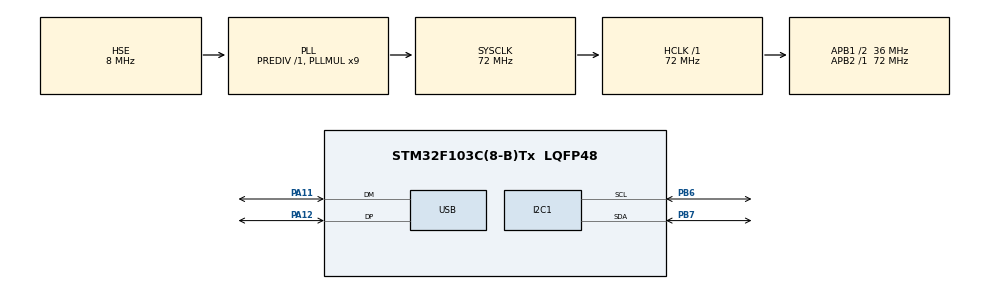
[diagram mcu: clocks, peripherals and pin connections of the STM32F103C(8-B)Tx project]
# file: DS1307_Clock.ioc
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Mcu.Family=STM32F1
Mcu.Name=STM32F103C(8-B)Tx
Mcu.Package=LQFP48
NVIC.PriorityGroup=NVIC_PRIORITYGROUP_4
NVIC.USB_LP_CAN1_RX0_IRQn=true\:0\:0\:false\:false\:true\:false\:true\:true
PA11.Mode=Device
PA11.Signal=USB_DM
PA12.Mode=Device
PA12.Signal=USB_DP
PA13.Mode=Serial_Wire
PA13.Signal=SYS_JTMS-SWDIO
PA14.Mode=Serial_Wire
PA14.Signal=SYS_JTCK-SWCLK
PB6.Mode=I2C
PB6.Signal=I2C1_SCL
PB7.Mode=I2C
PB7.Signal=I2C1_SDA
PD0-OSC_IN.Mode=HSE-External-Oscillator
PD0-OSC_IN.Signal=RCC_OSC_IN
PD1-OSC_OUT.Mode=HSE-External-Oscillator
PD1-OSC_OUT.Signal=RCC_OSC_OUT
ProjectManager.HeapSize=0x200
ProjectManager.StackSize=0x400
ProjectManager.TargetToolchain=STM32CubeIDE
RCC.AHBFreq_Value=72000000
RCC.APB1CLKDivider=RCC_HCLK_DIV2
RCC.APB1Freq_Value=36000000
RCC.APB1TimFreq_Value=72000000
RCC.APB2Freq_Value=72000000
RCC.APB2TimFreq_Value=72000000
RCC.HCLKFreq_Value=72000000
RCC.PLLMUL=RCC_PLL_MUL9
RCC.SYSCLKFreq_VALUE=72000000
RCC.SYSCLKSource=RCC_SYSCLKSOURCE_PLLCLK
RCC.USBFreq_Value=48000000
RCC.USBPrescaler=RCC_USBCLKSOURCE_PLL_DIV1_5
USB_DEVICE.CLASS_NAME_FS=CDC
USB_DEVICE.VirtualMode=Cdc
USB_DEVICE.VirtualModeFS=Cdc_FS
VP_USB_DEVICE_VS_USB_DEVICE_CDC_FS.Mode=CDC_FS
board=custom

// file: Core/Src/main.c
/* USER CODE BEGIN Header */
/**
  ******************************************************************************
  * @file           : main.c
  * @brief          : Main program body
  ******************************************************************************
  * @attention
  *
  * Copyright (c) 2024 STMicroelectronics.
  * All rights reserved.
  *
  * This software is licensed under terms that can be found in the LICENSE file
  * in the root directory of this software component.
  * If no LICENSE file comes with this software, it is provided AS-IS.
  *
  ******************************************************************************
  */
/* USER CODE END Header */
#include "main.h"
#include "usb_device.h"
#include "usbd_cdc_if.h"
#include "E:\Embedded\Cube\STM32F1\DS1307_Clock\Core\Lib\DS1307_hal.h"
#include "E:\Embedded\Cube\STM32F1\DS1307_Clock\Core\Lib\DS1307_hal.cpp"

I2C_HandleTypeDef hi2c1;

void SystemClock_Config(void);
static void MX_GPIO_Init(void);
static void MX_I2C1_Init(void);

int main(void)
{

  /* MCU Configuration--------------------------------------------------------*/

  /* Reset of all peripherals, Initializes the Flash interface and the Systick. */
  HAL_Init();

  /* Configure the system clock */
  SystemClock_Config();

  /* Initialize all configured peripherals */
  MX_GPIO_Init();
  MX_I2C1_Init();
  MX_USB_DEVICE_Init();
  /* USER CODE BEGIN 2 */
  const char *DAYS_OF_WEEK[7] = {"Sunday", "Monday", "Tuesday", "Wednesday", "Thursday", "Friday", "Saturday"};
  DS1307_Init(&hi2c1);
  DS1307_SetTimeZone(+8, 00);
  DS1307_SetDate(5);
  DS1307_SetMonth(4);
  DS1307_SetYear(2024);
  DS1307_SetDOW(5);
  DS1307_SetHour(11);
  DS1307_SetMin(18);
  DS1307_SetSec(0);
  /* USER CODE END 2 */

  /* Infinite loop */
  while (1)
  {
    int8_t date = DS1307_GetDate();
		uint8_t month = DS1307_GetMonth();
		uint16_t year = DS1307_GetYear();
		uint8_t dow = DS1307_GetDOW();
		uint8_t hour = DS1307_GetHour();
		uint8_t minute = DS1307_GetMin();
		uint8_t second = DS1307_GetSec();
		int8_t zone_hr = DS1307_GetTimeZoneHour();
		uint8_t zone_min = DS1307_GetTimeZoneMin();
		char buffer[100] = { 0 };
		sprintf(buffer, "ISO8601 FORMAT: %04d-%02d-%02dT%02d:%02d:%02d%+03d:%02d  %s\n",
				year, month, date, hour, minute, second, zone_hr, zone_min, DAYS_OF_WEEK[dow]);
		CDC_Transmit_FS((uint8_t*)buffer,strlen(buffer));
		HAL_Delay(250);
  }
}

void SystemClock_Config(void)
{
  RCC_OscInitTypeDef RCC_OscInitStruct = {0};
  RCC_ClkInitTypeDef RCC_ClkInitStruct = {0};
  RCC_PeriphCLKInitTypeDef PeriphClkInit = {0};

  /** Initializes the RCC Oscillators according to the specified parameters
  * in the RCC_OscInitTypeDef structure.
  */
  RCC_OscInitStruct.OscillatorType = RCC_OSCILLATORTYPE_HSE;
  RCC_OscInitStruct.HSEState = RCC_HSE_ON;
  RCC_OscInitStruct.HSEPredivValue = RCC_HSE_PREDIV_DIV1;
  RCC_OscInitStruct.HSIState = RCC_HSI_ON;
  RCC_OscInitStruct.PLL.PLLState = RCC_PLL_ON;
  RCC_OscInitStruct.PLL.PLLSource = RCC_PLLSOURCE_HSE;
  RCC_OscInitStruct.PLL.PLLMUL = RCC_PLL_MUL9;
  if (HAL_RCC_OscConfig(&RCC_OscInitStruct) != HAL_OK)
  {
    Error_Handler();
  }

  /** Initializes the CPU, AHB and APB buses clocks
  */
  RCC_ClkInitStruct.ClockType = RCC_CLOCKTYPE_HCLK|RCC_CLOCKTYPE_SYSCLK
                              |RCC_CLOCKTYPE_PCLK1|RCC_CLOCKTYPE_PCLK2;
  RCC_ClkInitStruct.SYSCLKSource = RCC_SYSCLKSOURCE_PLLCLK;
  RCC_ClkInitStruct.AHBCLKDivider = RCC_SYSCLK_DIV1;
  RCC_ClkInitStruct.APB1CLKDivider = RCC_HCLK_DIV2;
  RCC_ClkInitStruct.APB2CLKDivider = RCC_HCLK_DIV1;

  if (HAL_RCC_ClockConfig(&RCC_ClkInitStruct, FLASH_LATENCY_2) != HAL_OK)
  {
    Error_Handler();
  }
  PeriphClkInit.PeriphClockSelection = RCC_PERIPHCLK_USB;
  PeriphClkInit.UsbClockSelection = RCC_USBCLKSOURCE_PLL_DIV1_5;
  if (HAL_RCCEx_PeriphCLKConfig(&PeriphClkInit) != HAL_OK)
  {
    Error_Handler();
  }
}

static void MX_I2C1_Init(void)
{

  hi2c1.Instance = I2C1;
  hi2c1.Init.ClockSpeed = 100000;
  hi2c1.Init.DutyCycle = I2C_DUTYCYCLE_2;
  hi2c1.Init.OwnAddress1 = 0;
  hi2c1.Init.AddressingMode = I2C_ADDRESSINGMODE_7BIT;
  hi2c1.Init.DualAddressMode = I2C_DUALADDRESS_DISABLE;
  hi2c1.Init.OwnAddress2 = 0;
  hi2c1.Init.GeneralCallMode = I2C_GENERALCALL_DISABLE;
  hi2c1.Init.NoStretchMode = I2C_NOSTRETCH_DISABLE;
  if (HAL_I2C_Init(&hi2c1) != HAL_OK)
  {
    Error_Handler();
  }

}

static void MX_GPIO_Init(void)
{

  /* GPIO Ports Clock Enable */
  __HAL_RCC_GPIOD_CLK_ENABLE();
  __HAL_RCC_GPIOA_CLK_ENABLE();
  __HAL_RCC_GPIOB_CLK_ENABLE();

}

void Error_Handler(void)
{
  __disable_irq();
  while (1)
  {
  }
}
